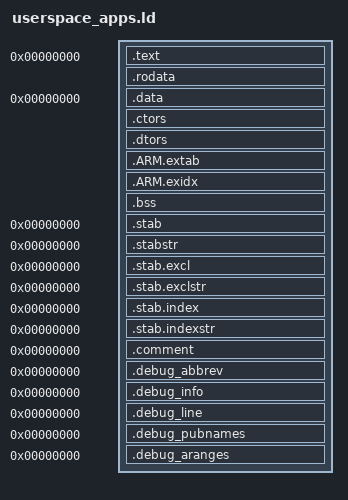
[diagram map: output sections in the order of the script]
/****************************************************************************
 *
 * Copyright 2019 Samsung Electronics All Rights Reserved.
 *
 * Licensed under the Apache License, Version 2.0 (the "License");
 * you may not use this file except in compliance with the License.
 * You may obtain a copy of the License at
 *
 * http://www.apache.org/licenses/LICENSE-2.0
 *
 * Unless required by applicable law or agreed to in writing,
 * software distributed under the License is distributed on an
 * "AS IS" BASIS, WITHOUT WARRANTIES OR CONDITIONS OF ANY KIND,
 * either express or implied. See the License for the specific
 * language governing permissions and limitations under the License.
 *
 ****************************************************************************/
/****************************************************************************
 * os/userspace/userspace_apps.ld
 *
 *   Copyright (C) 2012 Gregory Nutt. All rights reserved.
 *   Author: Gregory Nutt <gnutt@nuttx.org>
 *
 * Redistribution and use in source and binary forms, with or without
 * modification, are permitted provided that the following conditions
 * are met:
 *
 * 1. Redistributions of source code must retain the above copyright
 *    notice, this list of conditions and the following disclaimer.
 * 2. Redistributions in binary form must reproduce the above copyright
 *    notice, this list of conditions and the following disclaimer in
 *    the documentation and/or other materials provided with the
 *    distribution.
 * 3. Neither the name NuttX nor the names of its contributors may be
 *    used to endorse or promote products derived from this software
 *    without specific prior written permission.
 *
 * THIS SOFTWARE IS PROVIDED BY THE COPYRIGHT HOLDERS AND CONTRIBUTORS
 * "AS IS" AND ANY EXPRESS OR IMPLIED WARRANTIES, INCLUDING, BUT NOT
 * LIMITED TO, THE IMPLIED WARRANTIES OF MERCHANTABILITY AND FITNESS
 * FOR A PARTICULAR PURPOSE ARE DISCLAIMED. IN NO EVENT SHALL THE
 * COPYRIGHT OWNER OR CONTRIBUTORS BE LIABLE FOR ANY DIRECT, INDIRECT,
 * INCIDENTAL, SPECIAL, EXEMPLARY, OR CONSEQUENTIAL DAMAGES (INCLUDING,
 * BUT NOT LIMITED TO, PROCUREMENT OF SUBSTITUTE GOODS OR SERVICES; LOSS
 * OF USE, DATA, OR PROFITS; OR BUSINESS INTERRUPTION) HOWEVER CAUSED
 * AND ON ANY THEORY OF LIABILITY, WHETHER IN CONTRACT, STRICT
 * LIABILITY, OR TORT (INCLUDING NEGLIGENCE OR OTHERWISE) ARISING IN
 * ANY WAY OUT OF THE USE OF THIS SOFTWARE, EVEN IF ADVISED OF THE
 * POSSIBILITY OF SUCH DAMAGE.
 *
 ****************************************************************************/

SECTIONS
{
  .text 0x00000000 :
    {
      _stext_flash = . ;
      /* Place holder to keep the heap object at the top
       * 4 bytes is reserved at the top of the text segment,
       * which can be used to place user heap object, which
       * eventually used by user space memory allocator
       */
      LONG(0);
      KEEP(*(.userspace))
      *(.text)
      *(.text.*)
      *(.gnu.warning)
      *(.stub)
      *(.glue_7)
      *(.glue_7t)
      *(.jcr)

      /* C++ support:  The .init and .fini sections contain specific logic
       * to manage static constructors and destructors.
       */

      *(.gnu.linkonce.t.*)
      *(.init)             /* Old ABI */
      *(.fini)             /* Old ABI */
      _etext_flash = . ;
    }

  .rodata :
    {
      _srodata = . ;
      *(.rodata)
      *(.rodata1)
      *(.rodata.*)
      *(.gnu.linkonce.r*)
      _erodata = . ;
      _eronly = .;
    }

  .data 0x00000000 :
    {
      _sdata = . ;
      LONG(0);
      *(.curapp)
      *(.appheaptable)
      *(.data)
      *(.data1)
      *(.data.*)
      *(.gnu.linkonce.d*)
      _edata = . ;
    }

  /* C++ support. For each global and static local C++ object,
   * GCC creates a small subroutine to construct the object. Pointers
   * to these routines (not the routines themselves) are stored as
   * simple, linear arrays in the .ctors section of the object file.
   * Similarly, pointers to global/static destructor routines are
   * stored in .dtors.
   */

  .ctors :
    {
      _sctors = . ;
      *(.ctors)       /* Old ABI:  Unallocated */
      *(.init_array)  /* New ABI:  Allocated */
      _ectors = . ;
    }

  .dtors :
    {
      _sdtors = . ;
      *(.dtors)       /* Old ABI:  Unallocated */
      *(.fini_array)  /* New ABI:  Allocated */
      _edtors = . ;
    }

  .ARM.extab :
    {
      *(.ARM.extab*)
    }

  .ARM.exidx :
    {
      __exidx_start = . ;
      *(.ARM.exidx*)
      __exidx_end = . ;
    }

  .bss :
    {
      _sbss = . ;
      *(.bss)
      *(.bss.*)
      *(.sbss)
      *(.sbss.*)
      *(.gnu.linkonce.b*)
      *(COMMON)
      _ebss = . ;
    }

    /* Stabs debugging sections.    */

    .stab 0 : { *(.stab) }
    .stabstr 0 : { *(.stabstr) }
    .stab.excl 0 : { *(.stab.excl) }
    .stab.exclstr 0 : { *(.stab.exclstr) }
    .stab.index 0 : { *(.stab.index) }
    .stab.indexstr 0 : { *(.stab.indexstr) }
    .comment 0 : { *(.comment) }
    .debug_abbrev 0 : { *(.debug_abbrev) }
    .debug_info 0 : { *(.debug_info) }
    .debug_line 0 : { *(.debug_line) }
    .debug_pubnames 0 : { *(.debug_pubnames) }
    .debug_aranges 0 : { *(.debug_aranges) }
}
